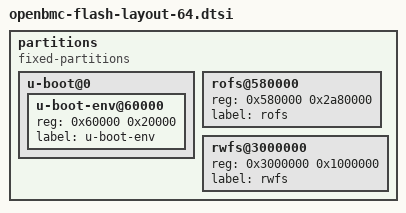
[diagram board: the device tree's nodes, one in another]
/* bench 194.1.0 1a5aa4a69814 */
/* bench 194.1.1 7c85d1b52cbc */
/* bench 194.1.2 0224c6660e82 */
/* bench 194.1.3 4dc61c049c76 */
/* bench 194.1.4 6eed0921d39c */
/* bench 194.1.5 812777b5b1d6 */
/* bench 194.1.6 876984778579 */
/* bench 194.1.7 5a48f2fb8624 */
/* bench 4801.2.0 b1e65a1debba */
/* bench 4801.2.1 63ac689787be */
/* bench 4801.2.2 eacd3994a921 */
/* bench 4801.2.3 282239a8c329 */
/* bench 4801.2.4 5567d37ea729 */
/* bench 4801.2.5 287b5d068aea */
/* bench 4801.2.6 9096696a821e */
/* bench 4801.2.7 2ad0c39a688b */
/* bench 4801.2.8 db7978faedd5 */
/* bench 4801.2.9 54541e882fc2 */
/* bench 4801.2.10 5d054066c27e */
/* bench 4801.2.11 c4d4d67f26cd */
/* bench 4801.2.12 8e22b14b6b63 */
/* bench 4801.2.13 f25fea80f940 */
/* bench 4801.2.14 7f40b6db2bcc */
/* bench 194.1.9 66b21f42b228 */
/* bench 194.1.10 5c3b4eaca650 */
/* bench 194.1.11 dcc55e5fb0b6 */
/* bench 194.1.12 9ff9f74de408 */
/* bench 194.1.13 6d6526149013 */
/* bench 194.1.14 9e121d63f76a */
/* bench 194.1.15 b6bddde2a0a1 */
// SPDX-License-Identifier: GPL-2.0+
/*
 * Copyright (C) 2020 Bytedance.
 */

partitions {
	compatible = "fixed-partitions";
	#address-cells = <1>;
	#size-cells = <1>;

	u-boot@0 {
/* bench 8875.0.0 83f992060256 */
/* bench 8875.0.1 a18b95139704 */
/* bench 8875.0.2 a71b78e92611 */
/* bench 8875.0.3 60af777a204b */
/* bench 8875.0.4 fbbc346b3d04 */
/* bench 8875.0.5 ebc501aa9257 */
/* bench 8875.0.6 490536cb7802 */
/* bench 8875.0.7 8a658c2e8af6 */
/* bench 8875.0.8 2c6fd512c994 */

	u-boot-env@60000 {
		reg = <0x60000 0x20000>; // 128KB
		label = "u-boot-env";
	};

/* bench 12620.0.0 08e0b0d9011e */
	};

	rofs@580000 {
		reg = <0x580000 0x2a80000>; // 42.5MB
		label = "rofs";
	};

	rwfs@3000000 {
		reg = <0x3000000 0x1000000>; // 16MB
		label = "rwfs";
	};
};
